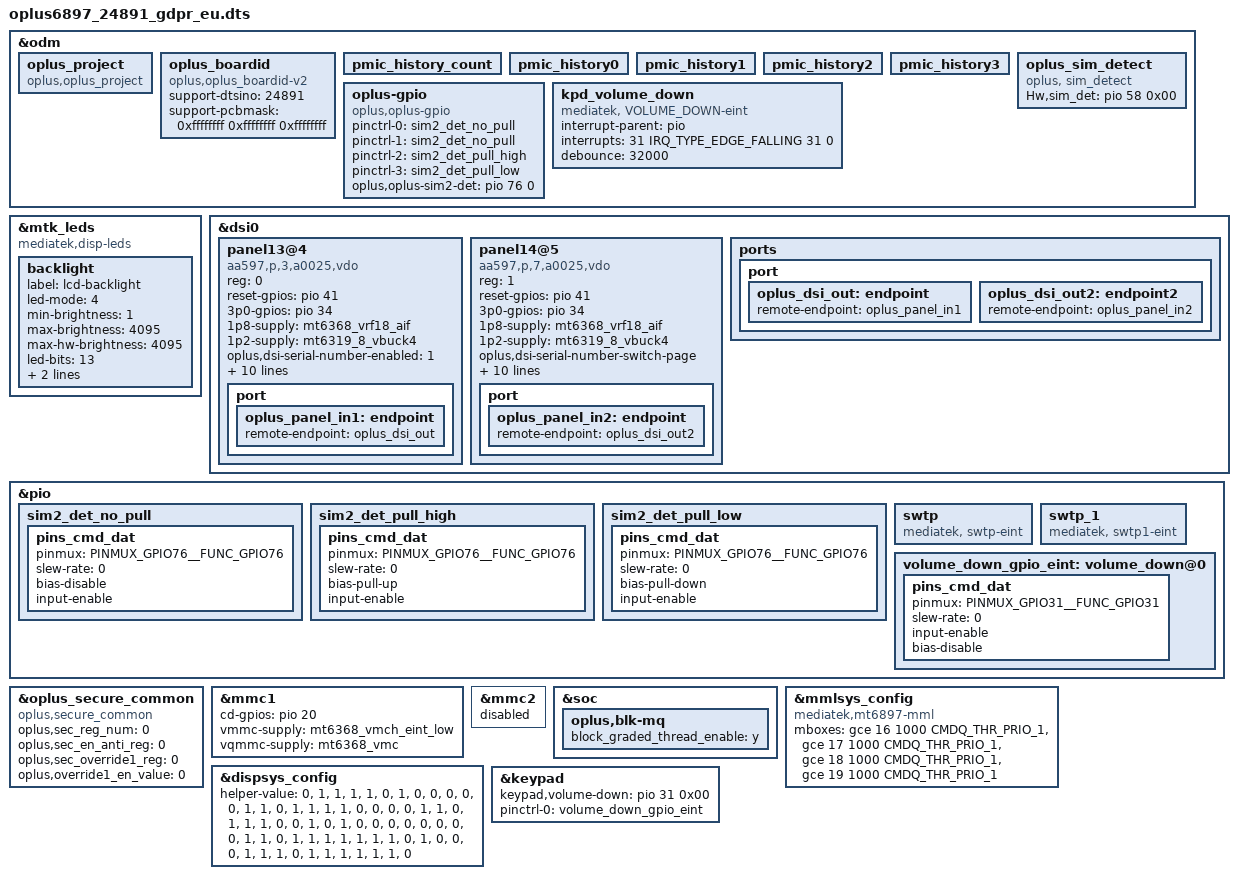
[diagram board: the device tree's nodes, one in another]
// SPDX-License-Identifier: (GPL-2.0 OR MIT)
/*
 * Copyright (C) 2022 MediaTek Inc.
 */
#include "k6897v1_64.dts"
#include <dt-bindings/phy/phy.h>
#include <dt-bindings/pinctrl/mt6897-pinfunc.h>
#include "mediatek/nfc/mt6897_24891_pn560.dtsi"
/* #ifdef OPLUS_FEATURE_CHG_BASIC */
#include "mediatek/oplus_charge_24891_gdpr_eu.dtsi"
#include "mediatek/oplus_misc_24891.dtsi"
/* #endif */

/* #ifdef OPLUS_FEATURE_SENSOR */
#include "mediatek/oplus_sensor_24891_gdpr.dtsi"
/* #endif */

/* Add for Honda(24891/24892) fingerprint device-tree */
/* #ifdef CONFIG_UFF_FINGERPRINT */
#include "mediatek/oplus_uff_24891.dtsi"
/* #endif CONFIG_UFF_FINGERPRINT */

#include "dt-bindings/gce/mt6897-gce.h"
&odm {
	/*OPLUS_FEATURE_OEM_OCDT oppo project start */
	oplus_project:oplus_project {
		compatible = "oplus,oplus_project";
	};
	oplus_boardid:oplus_boardid {
		compatible = "oplus,oplus_boardid-v2";
		support-dtsino=<24891>;//only one u32
		/*first one is low 32bit, last one is highest 32bit, must be 32-bit for 4gpios*/
		support-pcbmask=<0xffffffff 0xffffffff 0xffffffff>;
	};
	pmic_history_count:pmic_history_count {
	};
	pmic_history0:pmic_history0 {
	};
	pmic_history1:pmic_history1 {
	};
	pmic_history2:pmic_history2 {
	};
	pmic_history3:pmic_history3 {
	};
};

&mtk_leds {
	compatible = "mediatek,disp-leds";
	status = "okay";

	backlight {
		label = "lcd-backlight";
		led-mode = <4>;
		min-brightness = <1>;
		max-brightness = <4095>;
		max-hw-brightness = <4095>;
		led-bits = <13>;
		trans-bits = <13>;
		default-state = "on";
	};
};

&dsi0 {
	status = "okay";
	#address-cells = <1>;
	#size-cells = <0>;
	panel13@4 {
		compatible = "aa597,p,3,a0025,vdo";
		reg = <0>;
		reset-gpios = <&pio 41 0>;
		3p0-gpios = <&pio 34 0>;
		1p8-supply = <&mt6368_vrf18_aif>;
		1p2-supply = <&mt6319_8_vbuck4>;
		oplus,dsi-serial-number-enabled= <1>;
		oplus,dsi-serial-number-switch-page;
		oplus,dsi-serial-number-switch-page-command= <0xF0 0x55 0xAA 0x52 0x08 0x00>;
		oplus,dsi-serial-number-default-switch-page-command= <0xF0 0x55 0xAA 0x52 0x08 0x00>;
		oplus,dsi-serial-number-index= <0>;
		oplus,dsi-serial-number-reg= <0xA3>;
		oplus,dsi-serial-number-read-count= <7>;
		pinctrl-names = "default";
		oplus,ofp-fp-type = <0xA10>;
		oplus,ofp-fp-local-hbm-calibration;
		port {
			oplus_panel_in1: endpoint {
				remote-endpoint = <&oplus_dsi_out>;
			};
		};
	};
	panel14@5 {
		compatible = "aa597,p,7,a0025,vdo";
		reg = <1>;
		reset-gpios = <&pio 41 0>;
		3p0-gpios = <&pio 34 0>;
		1p8-supply = <&mt6368_vrf18_aif>;
		1p2-supply = <&mt6319_8_vbuck4>;
		oplus,dsi-serial-number-switch-page;
		oplus,dsi-serial-number-switch-page-command= <0xF0 0x55 0xAA 0x52 0x08 0x01>;
		oplus,dsi-serial-number-default-switch-page-command= <0xF0 0x55 0xAA 0x52 0x08 0x00>;
		oplus,dsi-serial-number-enabled= <1>;
		oplus,dsi-serial-number-index= <0>;
		oplus,dsi-serial-number-reg= <0xD7>;
		oplus,dsi-serial-number-read-count= <7>;
		pinctrl-names = "default";
		oplus,ofp-fp-type = <0xA10>;
		oplus,ofp-fp-local-hbm-calibration;
		port {
			oplus_panel_in2: endpoint {
				remote-endpoint = <&oplus_dsi_out2>;
			};
		};
	};
	ports {
		port {
			oplus_dsi_out: endpoint {
				remote-endpoint = <&oplus_panel_in1>;
			};
			oplus_dsi_out2: endpoint2 {
				remote-endpoint = <&oplus_panel_in2>;
			};
		};
	};
};

&odm {
/* Add for sim detect */
    oplus_sim_detect {
        compatible = "oplus, sim_detect";
        Hw,sim_det = <&pio 58 0x00>;
    };
};

//#ifdef OPLUS_FEATRUE_SIM_DETECT
&odm {
    oplus-gpio {
        compatible = "oplus,oplus-gpio";
        pinctrl-names = "default", "sim2_det_no_pull", "sim2_det_pull_high", "sim2_det_pull_low";
        pinctrl-0 = <&sim2_det_no_pull>;
        pinctrl-1 = <&sim2_det_no_pull>;
        pinctrl-2 = <&sim2_det_pull_high>;
        pinctrl-3 = <&sim2_det_pull_low>;
        oplus,oplus-sim2-det = <&pio 76 0>;
    };
};

&pio {
    sim2_det_no_pull: sim2_det_no_pull {
        pins_cmd_dat {
            pinmux = <PINMUX_GPIO76__FUNC_GPIO76>;
            slew-rate = <0>;
            bias-disable; /* NO pull */
            input-enable;
        };
    };

    sim2_det_pull_high: sim2_det_pull_high {
        pins_cmd_dat {
            pinmux = <PINMUX_GPIO76__FUNC_GPIO76>;
            slew-rate = <0>;
            bias-pull-up;
            input-enable;
        };
    };

    sim2_det_pull_low: sim2_det_pull_low {
        pins_cmd_dat {
            pinmux = <PINMUX_GPIO76__FUNC_GPIO76>;
            slew-rate = <0>;
            bias-pull-down;
            input-enable;
        };
    };
};

//Network RF add SWTP
&pio {
	//#ifdef OPLUS_VENDOR_SWTP
	swtp: swtp {
		compatible = "mediatek, swtp-eint";
	};
	swtp_1: swtp_1 {
		compatible = "mediatek, swtp1-eint";
	};
	//#endif  /*OPLUS_VENDOR_SWTP*/
};

&oplus_secure_common {
	compatible = "oplus,secure_common";
	oplus,sec_reg_num = <0>;
	oplus,sec_en_anti_reg = <0>;
	oplus,sec_override1_reg = <0>;
	oplus,override1_en_value = <0>;
};

&mmc1 {
	status = "okay";
	cd-gpios = <&pio 20 0>;
	vmmc-supply = <&mt6368_vmch_eint_low>;
	vqmmc-supply = <&mt6368_vmc>;
};

&mmc2 {
	status = "disabled";
};

&soc {
	oplus,blk-mq {
		block_graded_thread_enable = "y";
	};
};

&mmlsys_config {
	compatible = "mediatek,mt6897-mml";
	mboxes = <&gce 16 1000 CMDQ_THR_PRIO_1>,
		<&gce 17 1000 CMDQ_THR_PRIO_1>,
		<&gce 18 1000 CMDQ_THR_PRIO_1>,
		<&gce 19 1000 CMDQ_THR_PRIO_1>;
};

&dispsys_config {
	helper-value = <0>, /*MTK_DRM_OPT_STAGE*/
		<1>, /*MTK_DRM_OPT_USE_CMDQ*/
		<1>, /*MTK_DRM_OPT_USE_M4U*/
		<1>, /*MTK_DRM_OPT_MMQOS_SUPPORT*/
		<1>, /*MTK_DRM_OPT_MMDVFS_SUPPORT*/
		<0>, /*MTK_DRM_OPT_SODI_SUPPORT*/
		<1>, /*MTK_DRM_OPT_IDLE_MGR*/
		<0>, /*MTK_DRM_OPT_IDLEMGR_SWTCH_DECOUPLE*/
		<0>, /*MTK_DRM_OPT_IDLEMGR_BY_REPAINT*/
		<0>, /*MTK_DRM_OPT_IDLEMGR_ENTER_ULPS*/
		<0>, /*MTK_DRM_OPT_IDLEMGR_KEEP_LP11*/
		<0>, /*MTK_DRM_OPT_DYNAMIC_RDMA_GOLDEN_SETTING*/
		<1>, /*MTK_DRM_OPT_IDLEMGR_DISABLE_ROUTINE_IRQ*/
		<1>, /*MTK_DRM_OPT_IDLEMGR_ASYNC*/
		<0>, /*MTK_DRM_OPT_MET_LOG*/
		<1>, /*MTK_DRM_OPT_USE_PQ*/
		<1>, /*MTK_DRM_OPT_ESD_CHECK_RECOVERY*/
		<1>, /*MTK_DRM_OPT_ESD_CHECK_SWITCH*/
		<1>, /*MTK_DRM_OPT_PRESENT_FENCE*/
		<0>, /*MTK_DRM_OPT_RDMA_UNDERFLOW_AEE*/
		<0>, /*MTK_DRM_OPT_DSI_UNDERRUN_AEE*/
		<0>, /*MTK_DRM_OPT_ODDMR_OD_AEE*/
		<0>, /*MTK_DRM_OPT_ODDMR_DMR_AEE*/
		<1>, /*MTK_DRM_OPT_HRT*/
		<1>, /*MTK_DRM_OPT_HRT_MODE*/
		<0>, /*MTK_DRM_OPT_DELAYED_TRIGGER*/
		<1>, /*MTK_DRM_OPT_OVL_EXT_LAYER*/
		<1>, /*MTK_DRM_OPT_AOD*/
		<1>, /*MTK_DRM_OPT_RPO*/
		<0>, /*MTK_DRM_OPT_DUAL_PIPE*/
		<0>, /*MTK_DRM_OPT_DC_BY_HRT*/
		<1>, /*MTK_DRM_OPT_OVL_WCG*/
		<0>, /*MTK_DRM_OPT_OVL_SBCH*/
		<1>, /*MTK_DRM_OPT_COMMIT_NO_WAIT_VBLANK*/
		<0>, /*MTK_DRM_OPT_MET*/
		<0>, /*MTK_DRM_OPT_REG_PARSER_RAW_DUMP*/
		<0>, /*MTK_DRM_OPT_VP_PQ*/
		<0>, /*MTK_DRM_OPT_GAME_PQ*/
		<0>, /*MTK_DRM_OPT_MMPATH*/
		<0>, /*MTK_DRM_OPT_HBM*/
		<0>, /*MTK_DRM_OPT_VDS_PATH_SWITCH*/
		<0>, /*MTK_DRM_OPT_LAYER_REC*/
		<1>, /*MTK_DRM_OPT_CLEAR_LAYER*/
		<1>, /*MTK_DRM_OPT_LFR*/
		<0>, /*MTK_DRM_OPT_SF_PF*/
		<1>, /*MTK_DRM_OPT_DYN_MIPI_CHANGE*/
		<1>, /*MTK_DRM_OPT_PRIM_DUAL_PIPE*/
		<1>, /*MTK_DRM_OPT_MSYNC2_0*/
		<1>, /*MTK_DRM_OPT_MML_PRIMARY*/
		<1>, /*MTK_DRM_OPT_MML_SUPPORT_CMD_MODE*/
		<1>, /*MTK_DRM_OPT_MML_PQ*/
		<1>, /*MTK_DRM_OPT_MML_IR*/
		<0>, /*MTK_DRM_OPT_DUAL_TE*/
		<1>, /*MTK_DRM_OPT_RES_SWITCH*/
		<0>, /*MTK_DRM_OPT_PREFETCH_TE*/
		<0>, /*MTK_DRM_OPT_VIDLE_APSRC_OFF*/
		<0>, /*MTK_DRM_OPT_VIDLE_DSI_PLL_OFF*/
		<1>, /*MTK_DRM_OPT_CHECK_TRIGGER_MERGE*/
		<1>, /*MTK_DRM_OPT_VIRTUAL_DISP*/
		<1>, /*MTK_DRM_OPT_OVL_BW_MONITOR*/
		<0>, /*MTK_DRM_OPT_GPU_CACHE*/
		<1>, /*MTK_DRM_OPT_SPHRT*/
		<1>, /*MTK_DRM_OPT_SDPA_OVL_SWITCH*/
		<1>, /*MTK_DRM_OPT_HRT_BY_LARB*/
		<1>, /*MTK_DRM_OPT_RES_SWITCH_ON_AP*/
		<1>, /*MTK_DRM_OPT_TILE_OVERHEAD*/
		<1>, /*MTK_DRM_OPT_OVL_WCG_BY_COLOR_MODE*/
		<0>; /*MTK_DRM_OPT_VBLANK_CONFIG_REC*/
};

&keypad {
        keypad,volume-down = <&pio 31 0x00>;
        pinctrl-names = "volume_down_as_int";
        pinctrl-0 = <&volume_down_gpio_eint>;
        status = "okay";
};

&pio {
        volume_down_gpio_eint:volume_down@0{
                pins_cmd_dat {
                        pinmux = <PINMUX_GPIO31__FUNC_GPIO31>;
                        slew-rate = <0>;  /*direction 0:in, 1:out*/
                        input-enable;
                        bias-disable;
                };
        };
};

&odm {
        kpd_volume_down:kpd_volume_down {
                compatible = "mediatek, VOLUME_DOWN-eint";
                interrupt-parent = <&pio>;
                interrupts = <31 IRQ_TYPE_EDGE_FALLING 31 0>;
                debounce = <32000>;
                status = "okay";
        };
};

#include <oplus6897_24891/cust.dtsi>
#include "mediatek/cust_mt6897_honda_camera_v4l2.dtsi"
#include "oplus_ntc_24021.dtsi"
#include "oplus_tp_24891.dtsi"
#include "mediatek/cust_mt6897_24891_audio.dtsi"
#include "mediatek/cust_mt6897_24021_thermal.dtsi"
/*End of this file, DO NOT ADD ANYTHING HERE*/

